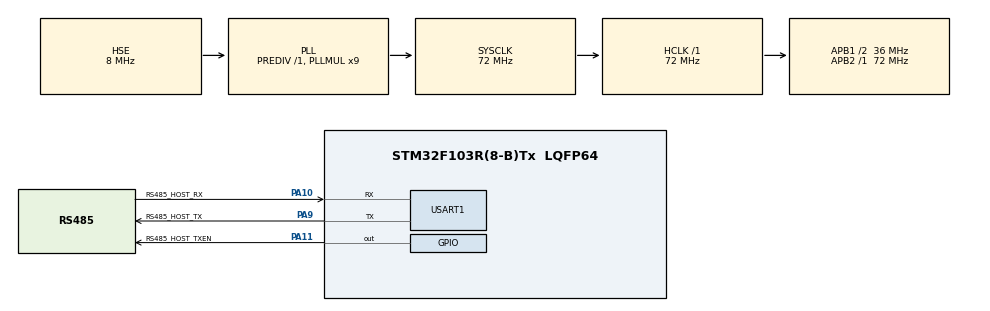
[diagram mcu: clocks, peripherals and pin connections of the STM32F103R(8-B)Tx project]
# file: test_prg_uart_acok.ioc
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Mcu.Family=STM32F1
Mcu.Name=STM32F103R(8-B)Tx
Mcu.Package=LQFP64
NVIC.PriorityGroup=NVIC_PRIORITYGROUP_4
NVIC.TIM2_IRQn=true\:0\:0\:false\:false\:true
NVIC.USART1_IRQn=true\:0\:0\:false\:false\:true
PA10.GPIO_Label=RS485_HOST_RX
PA10.GPIO_PuPd=GPIO_PULLUP
PA10.Mode=Asynchronous
PA10.Signal=USART1_RX
PA11.GPIO_Label=RS485_HOST_TXEN
PA11.Signal=GPIO_Output
PA13.Mode=Serial_Wire
PA13.Signal=SYS_JTMS-SWDIO
PA14.Mode=Serial_Wire
PA14.Signal=SYS_JTCK-SWCLK
PA9.GPIO_Label=RS485_HOST_TX
PA9.Mode=Asynchronous
PA9.Signal=USART1_TX
PC14-OSC32_IN.Mode=LSE-External-Oscillator
PC14-OSC32_IN.Signal=RCC_OSC32_IN
PC15-OSC32_OUT.Mode=LSE-External-Oscillator
PC15-OSC32_OUT.Signal=RCC_OSC32_OUT
PD0-OSC_IN.Mode=HSE-External-Oscillator
PD0-OSC_IN.Signal=RCC_OSC_IN
PD1-OSC_OUT.Mode=HSE-External-Oscillator
PD1-OSC_OUT.Signal=RCC_OSC_OUT
ProjectManager.HeapSize=0x200
ProjectManager.StackSize=0x400
ProjectManager.TargetToolchain=MDK-ARM V4
RCC.AHBFreq_Value=72000000
RCC.APB1CLKDivider=RCC_HCLK_DIV2
RCC.APB1Freq_Value=36000000
RCC.APB1TimFreq_Value=72000000
RCC.APB2Freq_Value=72000000
RCC.APB2TimFreq_Value=72000000
RCC.HCLKFreq_Value=72000000
RCC.HSIState=RCC_HSI_ON
RCC.PLLMUL=RCC_PLL_MUL9
RCC.PLLSourceVirtual=RCC_PLLSOURCE_HSE
RCC.SYSCLKFreq_VALUE=72000000
RCC.SYSCLKSource=RCC_SYSCLKSOURCE_PLLCLK
RCC.USBFreq_Value=72000000
VP_TIM2_VS_ClockSourceINT.Mode=Internal
board=test_prg_uart_acok

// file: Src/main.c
/**
  ******************************************************************************
  * File Name          : main.c
  * Description        : Main program body
  ******************************************************************************
  *
  * COPYRIGHT(c) 2016 STMicroelectronics
  *
  * Redistribution and use in source and binary forms, with or without modification,
  * are permitted provided that the following conditions are met:
  *   1. Redistributions of source code must retain the above copyright notice,
  *      this list of conditions and the following disclaimer.
  *   2. Redistributions in binary form must reproduce the above copyright notice,
  *      this list of conditions and the following disclaimer in the documentation
  *      and/or other materials provided with the distribution.
  *   3. Neither the name of STMicroelectronics nor the names of its contributors
  *      may be used to endorse or promote products derived from this software
  *      without specific prior written permission.
  *
  * THIS SOFTWARE IS PROVIDED BY THE COPYRIGHT HOLDERS AND CONTRIBUTORS "AS IS"
  * AND ANY EXPRESS OR IMPLIED WARRANTIES, INCLUDING, BUT NOT LIMITED TO, THE
  * IMPLIED WARRANTIES OF MERCHANTABILITY AND FITNESS FOR A PARTICULAR PURPOSE ARE
  * DISCLAIMED. IN NO EVENT SHALL THE COPYRIGHT HOLDER OR CONTRIBUTORS BE LIABLE
  * FOR ANY DIRECT, INDIRECT, INCIDENTAL, SPECIAL, EXEMPLARY, OR CONSEQUENTIAL
  * DAMAGES (INCLUDING, BUT NOT LIMITED TO, PROCUREMENT OF SUBSTITUTE GOODS OR
  * SERVICES; LOSS OF USE, DATA, OR PROFITS; OR BUSINESS INTERRUPTION) HOWEVER
  * CAUSED AND ON ANY THEORY OF LIABILITY, WHETHER IN CONTRACT, STRICT LIABILITY,
  * OR TORT (INCLUDING NEGLIGENCE OR OTHERWISE) ARISING IN ANY WAY OUT OF THE USE
  * OF THIS SOFTWARE, EVEN IF ADVISED OF THE POSSIBILITY OF SUCH DAMAGE.
  *
  ******************************************************************************
  */
#include "stm32f1xx_hal.h"

#include "tim.h"
#include "usart.h"

#include "gpio.h"
#include "main.h"
#include <mb_slave.h>
#include <modbus_config.h>
#include <stdbool.h>

//#include "mb.h"

#include <stm32f1xx_hal_flash.h>
#include <crc16.h>

/* USER CODE BEGIN PV */
/* Private variables ---------------------------------------------------------*/
		HAL_StatusTypeDef Flash_Status;
 mb_Regs Params;
	unsigned * BUF1 = (unsigned *) &(Params.dev_addr);
	unsigned * BUF2 = (unsigned *) FLASH_LOCATION;
	volatile uint32_t NbrOfPage = 0x00;
	uint32_t EraseCounter = 0x00, Address = 0x00;
	mb_Regs * Flash_Params = (mb_Regs *) FLASH_LOCATION;
	unsigned short * PARAMS_BUF = (unsigned short *) & (Params.dev_addr);

	uint32_t bps_list[5] = {9600,19200,38400,57600,115200};
	bool read_flash;
  uint16_t timer_ms;

		MbErrorCodes_t usart_init_msg;
/* USER CODE END PV */

void SystemClock_Config(void);
void Error_Handler(void);

/* USER CODE BEGIN PFP */
/* Private function prototypes -----------------------------------------------*/
		void usart_int_enable( void );
/* USER CODE END PFP */

int main(void)
{

  /* MCU Configuration----------------------------------------------------------*/

  /* Reset of all peripherals, Initializes the Flash interface and the Systick. */
  HAL_Init();

  /* Configure the system clock */
  SystemClock_Config();

  /* Initialize all configured peripherals */
  MX_GPIO_Init();
  MX_USART1_UART_Init();
  MX_TIM2_Init();

	HAL_GPIO_WritePin(GPIOA, GPIO_PIN_11, GPIO_PIN_SET);
  /* USER CODE BEGIN 2 */

//	HAL_TIM_Base_Start_IT(&htim2);

	NVIC_EnableIRQ(USART1_IRQn);
	usart_int_enable();
	__HAL_UART_ENABLE_IT(&huart1, UART_IT_RXNE);

  /* USER CODE BEGIN 2 */

  /* USER CODE END 2 */

  /* Infinite loop */
  /* USER CODE BEGIN WHILE */
	usart_init_msg = mb_slave_init( &m_mbParam );

	HAL_GPIO_WritePin(GPIOA, GPIO_PIN_11, GPIO_PIN_RESET);

  while (1)
  {
  /* USER CODE END WHILE */

  }

}

/** System Clock Configuration
*/
void SystemClock_Config(void)
{

  RCC_OscInitTypeDef RCC_OscInitStruct;
  RCC_ClkInitTypeDef RCC_ClkInitStruct;

  RCC_OscInitStruct.OscillatorType = RCC_OSCILLATORTYPE_HSE;
  RCC_OscInitStruct.HSEState = RCC_HSE_ON;
  RCC_OscInitStruct.HSEPredivValue = RCC_HSE_PREDIV_DIV1;
  RCC_OscInitStruct.PLL.PLLState = RCC_PLL_ON;
  RCC_OscInitStruct.PLL.PLLSource = RCC_PLLSOURCE_HSE;
  RCC_OscInitStruct.PLL.PLLMUL = RCC_PLL_MUL9;
  if (HAL_RCC_OscConfig(&RCC_OscInitStruct) != HAL_OK)
  {
    Error_Handler();
  }

  RCC_ClkInitStruct.ClockType = RCC_CLOCKTYPE_HCLK|RCC_CLOCKTYPE_SYSCLK
                              |RCC_CLOCKTYPE_PCLK1|RCC_CLOCKTYPE_PCLK2;
  RCC_ClkInitStruct.SYSCLKSource = RCC_SYSCLKSOURCE_PLLCLK;
  RCC_ClkInitStruct.AHBCLKDivider = RCC_SYSCLK_DIV1;
  RCC_ClkInitStruct.APB1CLKDivider = RCC_HCLK_DIV2;
  RCC_ClkInitStruct.APB2CLKDivider = RCC_HCLK_DIV1;
  if (HAL_RCC_ClockConfig(&RCC_ClkInitStruct, FLASH_LATENCY_2) != HAL_OK)
  {
    Error_Handler();
  }

  HAL_SYSTICK_Config(HAL_RCC_GetHCLKFreq()/1000);

  HAL_SYSTICK_CLKSourceConfig(SYSTICK_CLKSOURCE_HCLK);

  /* SysTick_IRQn interrupt configuration */
  HAL_NVIC_SetPriority(SysTick_IRQn, 0, 0);
}

/* USER CODE BEGIN 4 */

void USART1_IRQHandler(void)						// второе определение закомментировано в stm32f1xx_it.c
{

		HAL_UART_IRQHandler( &huart1 );
		return;

};

volatile int rxCount = 0;
void HAL_UART_RxCpltCallback(UART_HandleTypeDef *huart)
{
		static bool isRidgeEn = false;

		if( huart->Instance == USART1)
		{

			uint8_t data = (uint8_t)huart->Instance->DR;

			MbErrorCodes_t err_msg = mb_slave_recive( &m_mbParam, data );

		};

};

void HAL_UART_TxCpltCallback(UART_HandleTypeDef *huart)
{
	if( huart->Instance == USART1)
	{
	 if( huart->Instance == USART1 )
			mb_tx(&m_mbParam);
	}
};

void TIM2_IRQHandler( void )				// второе определение закомментировано в stm32f1xx_it.c
{
			__HAL_TIM_CLEAR_IT( &htim2, TIM_IT_UPDATE);
					mb_slave_timer_expired(&m_mbParam);

};

void usart_int_enable( void )
{

						// ???????????????????????????????????????????????
			/* Enable the UART Parity Error Interrupt */
			__HAL_UART_ENABLE_IT(&huart1, UART_IT_PE);

			/* Enable the UART Error Interrupt: (Frame error, noise error, overrun error) */
			__HAL_UART_ENABLE_IT(&huart1, UART_IT_ERR);

			/* Enable the UART Data Register not empty Interrupt */
			__HAL_UART_ENABLE_IT(&huart1, UART_IT_RXNE);

			__HAL_UART_ENABLE_IT(&huart1, UART_IT_TC);

		//	__HAL_UART_ENABLE_IT(&huart1, UART_IT_TXE);

};

uint32_t m_hostTimeout = 0;
bool m_isPasswordValid = false;
MbExceptionCodes_t mb_read_registers( uint8_t *lpDstBuf, uint16_t startAddr, uint16_t count ) {
	if(lpDstBuf == NULL)
		return MB_EXC_ILLEGAL_FUNCTION;

	m_hostTimeout = 0;
	m_isPasswordValid = false;
	uint16_t endAddr = startAddr + count;

	int registersCount = sizeof(Params) / 2;

	if(startAddr < registersCount) {
		// ?????? ???????????? ?????????
		if( endAddr > registersCount )
			return MB_EXC_ILLEGAL_DATA_ADDR;

		uint16_t *lpRegs = (uint16_t*)&Params;
		uint16_t reg;
		//
		for(uint32_t i = startAddr, j = 0; i < endAddr; i++, j += 2) {
			reg = lpRegs[i];
			lpDstBuf[j] = (uint8_t)(reg >> 8);
			lpDstBuf[j + 1] = (uint8_t)(reg);
		}
		//
		return MB_EXC_NONE;
	}

	return MB_EXC_ILLEGAL_FUNCTION;
};

MbExceptionCodes_t mb_write_registers( uint16_t startAddr, uint16_t count, uint8_t *lpSrcBuf ) {

	if(lpSrcBuf == NULL)
		return MB_EXC_ILLEGAL_FUNCTION;

	m_hostTimeout = 0;
	m_isPasswordValid = false;
	uint16_t endAddr = startAddr + count;
	uint16_t *tmp_ptr = (uint16_t *)&Params;

	for( int i = startAddr; i <= endAddr; i++)
	{

		tmp_ptr[i-1] = lpSrcBuf[i - startAddr];

	}

		//
		return MB_EXC_NONE;

	return MB_EXC_ILLEGAL_FUNCTION;

};

/* USER CODE END 4 */

void Error_Handler(void)
{
  while(1)
  {
  }
}

/************************ (C) COPYRIGHT STMicroelectronics *****END OF FILE****/
